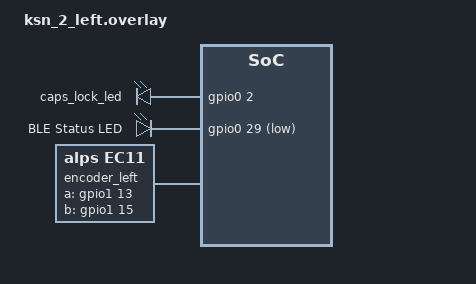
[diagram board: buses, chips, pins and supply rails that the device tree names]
#include "ksn_2.dtsi"
#include <dt-bindings/zmk/hid_indicators.h>

/ {
    /*
     * Left-side LEDs:
     *  CapsLock LED = D19 = P0.02  (pin21)
     *  BLE/COND LED = D20 = P0.29  (pin20)
     *
     * Left-side encoder:
     *  EN1 (A) = D15 = P1.15  (pin18)
     *  EN2 (B) = D14 = P1.13  (pin17)
     */

    leds {
        compatible = "gpio-leds";
        caps_lock_led: caps_lock_led {
            gpios = <&gpio0 2 GPIO_ACTIVE_HIGH>;   /* D19 = P0.02 */
        };
        ble_led: led_1 {
            gpios = <&gpio0 29 GPIO_ACTIVE_LOW>;   /* D20 = P0.29 */
            label = "BLE Status LED";
        };
    };

    indicators {
        compatible = "zmk,indicator-leds";
        caps_lock_indicator: caps_lock {
            indicator = <HID_INDICATOR_CAPS_LOCK>;
            leds = <&caps_lock_led>;
        };
    };

    aliases {
        indicator-led = &ble_led;
    };

    /* 회전 방향 반대로 요청(2026-09-05): quadrature 인코더는 A/B 채널이 감지되는
       순서로 방향을 판별하므로, a-gpios/b-gpios를 서로 맞바꾸면 배선을 그대로 두고도
       소프트웨어적으로 방향이 뒤집힘. 물리 핀(P1.15=EN1, P1.13=EN2)은 그대로이고
       ZMK가 어느 쪽을 "A"로 읽을지만 바뀜. steps/triggers-per-rotation 등 다른 설정은
       영향 없음 — sensor-bindings 쪽 바인딩 순서(<CW>, <CCW>)를 건드리는 것과 결과는
       같지만, 인코더 하나에 물린 모든 레이어(볼륨/백라이트)가 한 번에 일괄 반전되므로
       이 방식을 택함. */
    encoder_left: encoder_left {
        compatible = "alps,ec11";
        a-gpios = <&gpio1 13 (GPIO_ACTIVE_HIGH | GPIO_PULL_UP)>;  /* EN2 = D14 = P1.13 (기존 b-gpios) */
        b-gpios = <&gpio1 15 (GPIO_ACTIVE_HIGH | GPIO_PULL_UP)>;  /* EN1 = D15 = P1.15 (기존 a-gpios) */
        steps = <80>;
        status = "okay";
    };

    sensors {
        compatible            = "zmk,keymap-sensors";
        sensors               = <&encoder_left>;
        triggers-per-rotation = <20>;
    };
};
